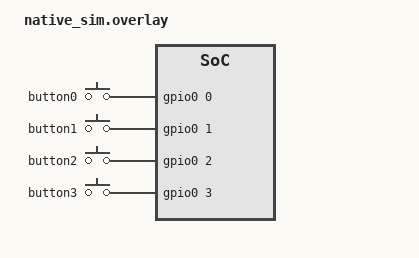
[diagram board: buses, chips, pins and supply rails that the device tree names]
/*
 * Copyright (c) 2026 Xiaomi Corporation
 *
 * SPDX-License-Identifier: Apache-2.0
 */

#include <zephyr/dt-bindings/input/input-event-codes.h>

/ {
	aliases {
		sw0 = &button0;
		sw1 = &button1;
		sw2 = &button2;
		sw3 = &button3;
	};

	gpio_keys {
		compatible = "gpio-keys";

		button0: button_0 {
			gpios = <&gpio0 0 GPIO_ACTIVE_HIGH>;
			zephyr,code = <INPUT_KEY_0>;
		};

		button1: button_1 {
			gpios = <&gpio0 1 GPIO_ACTIVE_HIGH>;
			zephyr,code = <INPUT_KEY_1>;
		};

		button2: button_2 {
			gpios = <&gpio0 2 GPIO_ACTIVE_HIGH>;
			zephyr,code = <INPUT_KEY_2>;
		};

		button3: button_3 {
			gpios = <&gpio0 3 GPIO_ACTIVE_HIGH>;
			zephyr,code = <INPUT_KEY_3>;
		};
	};
};
